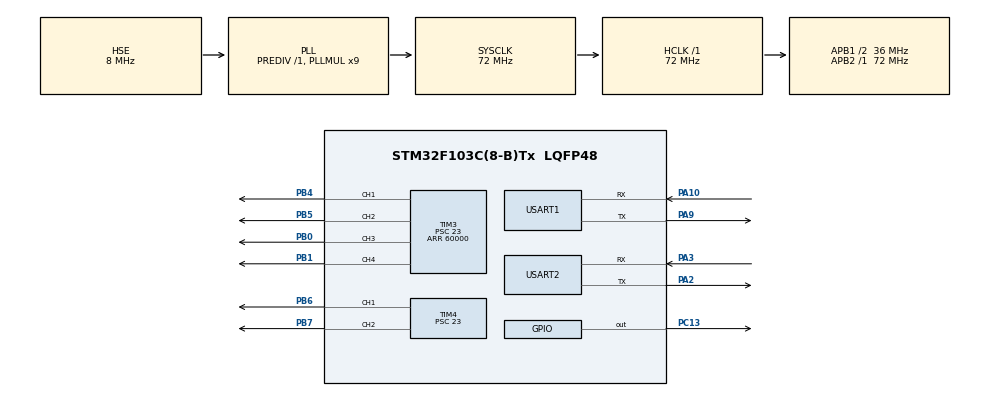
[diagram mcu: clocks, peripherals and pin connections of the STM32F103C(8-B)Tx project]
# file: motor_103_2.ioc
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Mcu.Family=STM32F1
Mcu.Name=STM32F103C(8-B)Tx
Mcu.Package=LQFP48
NVIC.PriorityGroup=NVIC_PRIORITYGROUP_4
NVIC.TIM2_IRQn=true\:0\:0\:false\:true\:true\:1\:true
NVIC.USART1_IRQn=true\:0\:0\:false\:true\:true\:2\:true
PA10.Mode=Asynchronous
PA10.Signal=USART1_RX
PA2.Mode=Asynchronous
PA2.Signal=USART2_TX
PA3.Mode=Asynchronous
PA3.Signal=USART2_RX
PA9.Mode=Asynchronous
PA9.Signal=USART1_TX
PB0.GPIO_Speed=GPIO_SPEED_FREQ_HIGH
PB0.Signal=S_TIM3_CH3
PB1.GPIO_Speed=GPIO_SPEED_FREQ_HIGH
PB1.Signal=S_TIM3_CH4
PB4.GPIO_Speed=GPIO_SPEED_FREQ_HIGH
PB4.Signal=S_TIM3_CH1
PB5.GPIO_Speed=GPIO_SPEED_FREQ_HIGH
PB5.Signal=S_TIM3_CH2
PB6.Signal=S_TIM4_CH1
PB7.Signal=S_TIM4_CH2
PC13-TAMPER-RTC.Signal=GPIO_Output
PC14-OSC32_IN.Mode=LSE-External-Oscillator
PC14-OSC32_IN.Signal=RCC_OSC32_IN
PC15-OSC32_OUT.Mode=LSE-External-Oscillator
PC15-OSC32_OUT.Signal=RCC_OSC32_OUT
PD0-OSC_IN.Mode=HSE-External-Oscillator
PD0-OSC_IN.Signal=RCC_OSC_IN
PD1-OSC_OUT.Mode=HSE-External-Oscillator
PD1-OSC_OUT.Signal=RCC_OSC_OUT
ProjectManager.HeapSize=0x800
ProjectManager.StackSize=0x800
ProjectManager.TargetToolchain=SW4STM32
RCC.AHBFreq_Value=72000000
RCC.APB1CLKDivider=RCC_HCLK_DIV2
RCC.APB1Freq_Value=36000000
RCC.APB1TimFreq_Value=72000000
RCC.APB2Freq_Value=72000000
RCC.APB2TimFreq_Value=72000000
RCC.HCLKFreq_Value=72000000
RCC.PLLMUL=RCC_PLL_MUL9
RCC.PLLSourceVirtual=RCC_PLLSOURCE_HSE
RCC.SYSCLKFreq_VALUE=72000000
RCC.SYSCLKSource=RCC_SYSCLKSOURCE_PLLCLK
RCC.USBFreq_Value=72000000
SH.S_TIM3_CH1.0=TIM3_CH1,PWM Generation1 CH1
SH.S_TIM3_CH2.0=TIM3_CH2,PWM Generation2 CH2
SH.S_TIM3_CH3.0=TIM3_CH3,PWM Generation3 CH3
SH.S_TIM3_CH4.0=TIM3_CH4,PWM Generation4 CH4
SH.S_TIM4_CH1.0=TIM4_CH1,PWM Generation1 CH1
SH.S_TIM4_CH2.0=TIM4_CH2,PWM Generation2 CH2
TIM2.AutoReloadPreload=TIM_AUTORELOAD_PRELOAD_ENABLE
TIM2.Period=60000
TIM2.Prescaler=23
TIM3.AutoReloadPreload=TIM_AUTORELOAD_PRELOAD_ENABLE
TIM3.Channel-PWM\ Generation1\ CH1=TIM_CHANNEL_1
TIM3.Channel-PWM\ Generation2\ CH2=TIM_CHANNEL_2
TIM3.Channel-PWM\ Generation3\ CH3=TIM_CHANNEL_3
TIM3.Channel-PWM\ Generation4\ CH4=TIM_CHANNEL_4
TIM3.ClockDivision=TIM_CLOCKDIVISION_DIV1
TIM3.Period=60000
TIM3.Prescaler=23
TIM3.TIM_MasterOutputTrigger=TIM_TRGO_ENABLE
TIM4.AutoReloadPreload=TIM_AUTORELOAD_PRELOAD_ENABLE
TIM4.Channel-PWM\ Generation1\ CH1=TIM_CHANNEL_1
TIM4.Channel-PWM\ Generation2\ CH2=TIM_CHANNEL_2
TIM4.Period=60000
TIM4.Prescaler=23
USART1.VirtualMode=VM_ASYNC
USART2.VirtualMode=VM_ASYNC
VP_SYS_VS_ND.Mode=No_Debug
VP_TIM2_VS_ClockSourceINT.Mode=Internal
VP_TIM2_VS_ClockSourceITR.Mode=TriggerSource_ITR0
board=motor_103_2

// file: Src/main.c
/**
  ******************************************************************************
  * @file           : main.c
  * @brief          : Main program body
  ******************************************************************************
  ** This notice applies to any and all portions of this file
  * that are not between comment pairs USER CODE BEGIN and
  * USER CODE END. Other portions of this file, whether
  * inserted by the user or by software development tools
  * are owned by their respective copyright owners.
  *
  * COPYRIGHT(c) 2018 STMicroelectronics
  *
  * Redistribution and use in source and binary forms, with or without modification,
  * are permitted provided that the following conditions are met:
  *   1. Redistributions of source code must retain the above copyright notice,
  *      this list of conditions and the following disclaimer.
  *   2. Redistributions in binary form must reproduce the above copyright notice,
  *      this list of conditions and the following disclaimer in the documentation
  *      and/or other materials provided with the distribution.
  *   3. Neither the name of STMicroelectronics nor the names of its contributors
  *      may be used to endorse or promote products derived from this software
  *      without specific prior written permission.
  *
  * THIS SOFTWARE IS PROVIDED BY THE COPYRIGHT HOLDERS AND CONTRIBUTORS "AS IS"
  * AND ANY EXPRESS OR IMPLIED WARRANTIES, INCLUDING, BUT NOT LIMITED TO, THE
  * IMPLIED WARRANTIES OF MERCHANTABILITY AND FITNESS FOR A PARTICULAR PURPOSE ARE
  * DISCLAIMED. IN NO EVENT SHALL THE COPYRIGHT HOLDER OR CONTRIBUTORS BE LIABLE
  * FOR ANY DIRECT, INDIRECT, INCIDENTAL, SPECIAL, EXEMPLARY, OR CONSEQUENTIAL
  * DAMAGES (INCLUDING, BUT NOT LIMITED TO, PROCUREMENT OF SUBSTITUTE GOODS OR
  * SERVICES; LOSS OF USE, DATA, OR PROFITS; OR BUSINESS INTERRUPTION) HOWEVER
  * CAUSED AND ON ANY THEORY OF LIABILITY, WHETHER IN CONTRACT, STRICT LIABILITY,
  * OR TORT (INCLUDING NEGLIGENCE OR OTHERWISE) ARISING IN ANY WAY OUT OF THE USE
  * OF THIS SOFTWARE, EVEN IF ADVISED OF THE POSSIBILITY OF SUCH DAMAGE.
  *
  ******************************************************************************
  */
#include "main.h"
#include "stm32f1xx_hal.h"
#include "tim.h"
#include "usart.h"
#include "gpio.h"

/* USER CODE BEGIN Includes */
//<<<<<<<<<<<<<<<<<<<<<<<<<<<<<<<<<<<<<<<<<<<<<<<<<<<<<<<<<<<<<<<<<<<<<<<<<<
#include "../Inc/myMain.h"  //<<<<<<<<<<<<<<<<<<<<<<<<<<<<<<<<<<<<<<<<<<<<<<
//<<<<<<<<<<<<<<<<<<<<<<<<<<<<<<<<<<<<<<<<<<<<<<<<<<<<<<<<<<<<<<<<<<<<<<<<<<
/* USER CODE END Includes */

/* USER CODE BEGIN PV */
/* Private variables ---------------------------------------------------------*/

/* USER CODE END PV */

void SystemClock_Config(void);
static void MX_NVIC_Init(void);

/* USER CODE BEGIN PFP */
/* Private function prototypes -----------------------------------------------*/

/* USER CODE END PFP */

int main(void)
{

  /* MCU Configuration----------------------------------------------------------*/

  /* Reset of all peripherals, Initializes the Flash interface and the Systick. */
  HAL_Init();

  /* Configure the system clock */
  SystemClock_Config();

  /* Initialize all configured peripherals */
  MX_GPIO_Init();
  MX_USART1_UART_Init();
  MX_USART2_UART_Init();
  MX_TIM3_Init();
  MX_TIM4_Init();
  MX_TIM2_Init();

  /* Initialize interrupts */
  MX_NVIC_Init();

  /* Infinite loop */
  /* USER CODE BEGIN WHILE */
  //<<<<<<<<<<<<<<<<<<<<<<<<<<<<<<<<<<<<<<<<<<<<<<<<<<<<<<<<<<<<<<<<<<<<<<<<<<
  myMain();  //<<<<<<< 把這個檔案視為初始化之用，在這裡放一個插入點跑真正的main() <<<<
  //<<<<<<<<<<<<<<<<<<<<<<<<<<<<<<<<<<<<<<<<<<<<<<<<<<<<<<<<<<<<<<<<<<<<<<<<<<
  HAL_GPIO_TogglePin(GPIOC,GPIO_PIN_13);
  while (1)
  {
  /* USER CODE END WHILE */

  }

}

void SystemClock_Config(void)
{

  RCC_OscInitTypeDef RCC_OscInitStruct;
  RCC_ClkInitTypeDef RCC_ClkInitStruct;

    /**Initializes the CPU, AHB and APB busses clocks
    */
  RCC_OscInitStruct.OscillatorType = RCC_OSCILLATORTYPE_HSE;
  RCC_OscInitStruct.HSEState = RCC_HSE_ON;
  RCC_OscInitStruct.HSEPredivValue = RCC_HSE_PREDIV_DIV1;
  RCC_OscInitStruct.HSIState = RCC_HSI_ON;
  RCC_OscInitStruct.PLL.PLLState = RCC_PLL_ON;
  RCC_OscInitStruct.PLL.PLLSource = RCC_PLLSOURCE_HSE;
  RCC_OscInitStruct.PLL.PLLMUL = RCC_PLL_MUL9;
  if (HAL_RCC_OscConfig(&RCC_OscInitStruct) != HAL_OK)
  {
    _Error_Handler(__FILE__, __LINE__);
  }

    /**Initializes the CPU, AHB and APB busses clocks
    */
  RCC_ClkInitStruct.ClockType = RCC_CLOCKTYPE_HCLK|RCC_CLOCKTYPE_SYSCLK
                              |RCC_CLOCKTYPE_PCLK1|RCC_CLOCKTYPE_PCLK2;
  RCC_ClkInitStruct.SYSCLKSource = RCC_SYSCLKSOURCE_PLLCLK;
  RCC_ClkInitStruct.AHBCLKDivider = RCC_SYSCLK_DIV1;
  RCC_ClkInitStruct.APB1CLKDivider = RCC_HCLK_DIV2;
  RCC_ClkInitStruct.APB2CLKDivider = RCC_HCLK_DIV1;

  if (HAL_RCC_ClockConfig(&RCC_ClkInitStruct, FLASH_LATENCY_2) != HAL_OK)
  {
    _Error_Handler(__FILE__, __LINE__);
  }

    /**Configure the Systick interrupt time
    */
  HAL_SYSTICK_Config(HAL_RCC_GetHCLKFreq()/1000);

    /**Configure the Systick
    */
  HAL_SYSTICK_CLKSourceConfig(SYSTICK_CLKSOURCE_HCLK);

  /* SysTick_IRQn interrupt configuration */
  HAL_NVIC_SetPriority(SysTick_IRQn, 0, 0);
}

/**
  * @brief NVIC Configuration.
  * @retval None
  */
static void MX_NVIC_Init(void)
{
  /* TIM2_IRQn interrupt configuration */
  HAL_NVIC_SetPriority(TIM2_IRQn, 3, 0);
  HAL_NVIC_EnableIRQ(TIM2_IRQn);
  /* USART1_IRQn interrupt configuration */
  HAL_NVIC_SetPriority(USART1_IRQn, 5, 0);
  HAL_NVIC_EnableIRQ(USART1_IRQn);
}

void _Error_Handler(char *file, int line)
{
  while(1)
  {
  }
}

/************************ (C) COPYRIGHT STMicroelectronics *****END OF FILE****/
